# nrf9230_engb_celldsp register map
Vendor: Nordic Semiconductor; Series: nRF92; File version: 1
Registers are 32-bit, read-write, reset 0x0 unless marked. A register's access mark holds for its fields unless they carry their own. Offsets are from the block's base; [hi:lo] are bit positions; 'fields as' and 'values as' point back to an identical list.

## TURBO1 — Decoding 0
Base 0x45009000
Same registers: TURBO0 0x4500B000
0x00 LTETURBODECTASKS wo — Task vector: bit3-SRAMDMASTART bit2-TCMDMASTART bit1-CORESTOP bit0-CORESTART
  [3:0] LTETURBODECTASKS — Task vector - write 1 to position 0 to 3 triggers task
    on write: 1=CoreStart (Start turbo core); 2=CoreStop (Force turbo core stop); 4=TCMDMAStart (Start data read from DSP memory); 8=SRAMDMAStart (Start data write to SRAM)
0x04 TASKS_CORESTART wo — Start Turbo core
  [0] TASKS_CORESTART
    1=Trigger task
0x08 TASKS_CORESTOP wo — Stop Turbo core (forced stop). Decoder stops when on going iteration is ready.
  [0] TASKS_CORESTOP
    1=Trigger task
0x0C TASKS_TCMDMASTART wo — Start data transfer from DSP TCM memory
  [0] TASKS_TCMDMASTART
    1=Trigger task
0x10 TASKS_SRAMDMASTART wo — Start data transfer to MCU SRAM
  [0] TASKS_SRAMDMASTART
    1=Trigger task
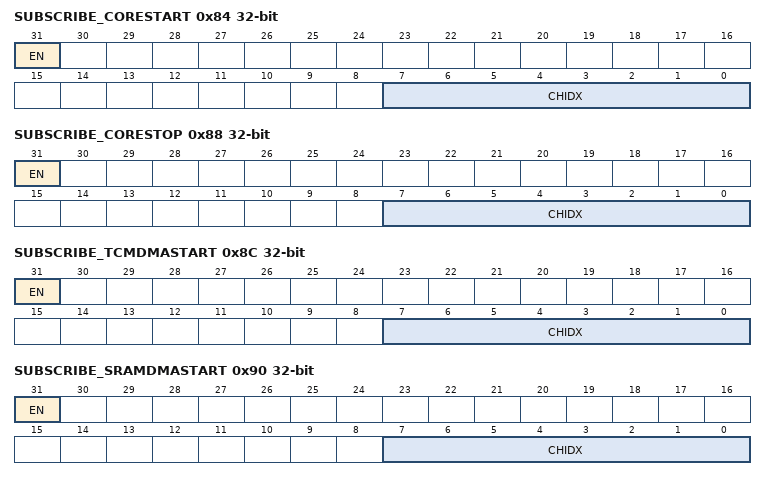
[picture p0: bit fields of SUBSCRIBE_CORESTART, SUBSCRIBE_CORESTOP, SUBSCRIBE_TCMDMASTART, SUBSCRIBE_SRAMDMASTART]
0x84 SUBSCRIBE_CORESTART — Subscribe configuration for task CORESTART
  [31] EN
    0=Disabled (Disable subscription); 1=Enabled (Enable subscription)
  [7:0] CHIDX — DPPI channel that task CORESTART will subscribe to
0x88 SUBSCRIBE_CORESTOP — Subscribe configuration for task CORESTOP
  [31] EN
    values as SUBSCRIBE_CORESTART.EN
  [7:0] CHIDX — DPPI channel that task CORESTOP will subscribe to
0x8C SUBSCRIBE_TCMDMASTART — Subscribe configuration for task TCMDMASTART
  [31] EN
    values as SUBSCRIBE_CORESTART.EN
  [7:0] CHIDX — DPPI channel that task TCMDMASTART will subscribe to
0x90 SUBSCRIBE_SRAMDMASTART — Subscribe configuration for task SRAMDMASTART
  [31] EN
    values as SUBSCRIBE_CORESTART.EN
  [7:0] CHIDX — DPPI channel that task SRAMDMASTART will subscribe to
0x100 LTETURBODECEVENTS ro — Event vector - Reserved (Not used)
  [6:0] LTETURBODECEVENTS — Event vector. Reserved. Always zero
    on read: 0=NotUsed (Read: all zero); 1=Core (Decoder done - bit1 - reg 0x104, write set val = 0x1); 2=DMATCM (TCM DMA transfer done - reg 0x108, write set val = 0x1); 4=DMASRAM (SRAM DMA transfer done - reg 0x10C, write set val = 0x1); 8=NoDMASRAM (CRC failed - No SRAM DMA - reg 0x110, write set val = 0x1); 16=DMATCMFail (TCM DMA bus error detected - reg 0x114, write set val = 0x1); 32=DMASRAMFail (SRAM DMA bus error detected - reg 0x118, write set val = 0x1)
0x104 EVENTS_CORE — Decoder done
  [0] EVENTS_CORE
    0=NotGenerated (Event not generated); 1=Generated (Event generated)
0x108 EVENTS_DMATCM — TCM DMA transfer done
  [0] EVENTS_DMATCM
    values as EVENTS_CORE.EVENTS_CORE
0x10C EVENTS_DMASRAM — SRAM DMA transfer done
  [0] EVENTS_DMASRAM
    values as EVENTS_CORE.EVENTS_CORE
0x110 EVENTS_NODMASRAM — CRC failed - No SRAM DMA
  [0] EVENTS_NODMASRAM
    values as EVENTS_CORE.EVENTS_CORE
0x114 EVENTS_DMATCMFAIL — TCM DMA bus error detected
  [0] EVENTS_DMATCMFAIL
    values as EVENTS_CORE.EVENTS_CORE
0x118 EVENTS_DMASRAMFAIL — SRAM DMA bus error detected
  [0] EVENTS_DMASRAMFAIL
    values as EVENTS_CORE.EVENTS_CORE
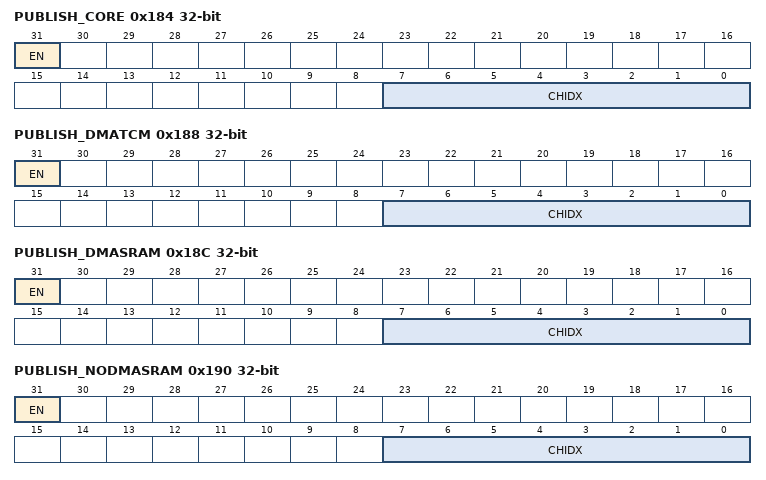
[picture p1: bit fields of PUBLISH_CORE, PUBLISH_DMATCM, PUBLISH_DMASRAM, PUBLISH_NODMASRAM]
0x184 PUBLISH_CORE — Publish configuration for event CORE
  [31] EN
    0=Disabled (Disable publishing); 1=Enabled (Enable publishing)
  [7:0] CHIDX — DPPI channel that event CORE will publish to
0x188 PUBLISH_DMATCM — Publish configuration for event DMATCM
  [31] EN
    values as PUBLISH_CORE.EN
  [7:0] CHIDX — DPPI channel that event DMATCM will publish to
0x18C PUBLISH_DMASRAM — Publish configuration for event DMASRAM
  [31] EN
    values as PUBLISH_CORE.EN
  [7:0] CHIDX — DPPI channel that event DMASRAM will publish to
0x190 PUBLISH_NODMASRAM — Publish configuration for event NODMASRAM
  [31] EN
    values as PUBLISH_CORE.EN
  [7:0] CHIDX — DPPI channel that event NODMASRAM will publish to
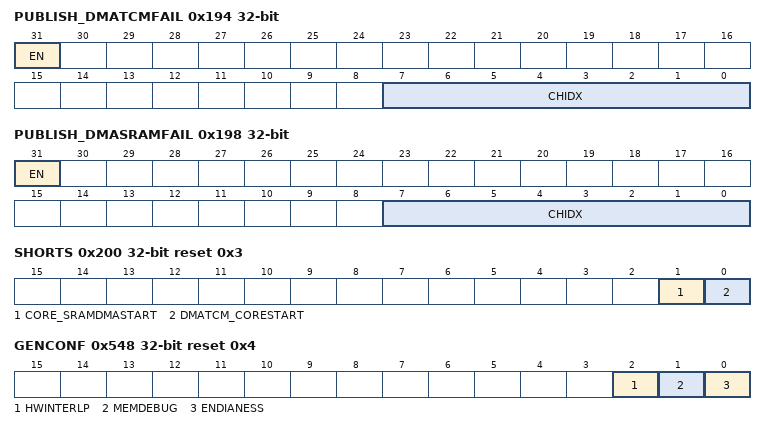
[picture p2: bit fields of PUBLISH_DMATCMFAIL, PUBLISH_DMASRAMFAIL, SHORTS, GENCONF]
0x194 PUBLISH_DMATCMFAIL — Publish configuration for event DMATCMFAIL
  [31] EN
    values as PUBLISH_CORE.EN
  [7:0] CHIDX — DPPI channel that event DMATCMFAIL will publish to
0x198 PUBLISH_DMASRAMFAIL — Publish configuration for event DMASRAMFAIL
  [31] EN
    values as PUBLISH_CORE.EN
  [7:0] CHIDX — DPPI channel that event DMASRAMFAIL will publish to
0x200 SHORTS ro reset 0x3 — Shortcut register
  [1] CORE_SRAMDMASTART — Shortcut between CORE event and SRAMDMASTART task
    on read: 1=Enabled (Shortcut enabled); 0=Disabled (Shortcut disabled)
  [0] DMATCM_CORESTART — Shortcut between DMATCM event and CORESTART task
    values as CORE_SRAMDMASTART
0x204 SET_TCMDONE_CORESTART wo — Enable shortcut
  [0] TCMDONE_CORESTART — Write '1' to Enable TCMDONE to CORESTART shortcut
    on write: 1=Set (Enable)
0x208 CLR_TCMDONE_CORESTART wo — Disable shortcut
  [0] TCMDONE_CORESTART — Write '1' to Disable TCMDONE to CORESTART shortcut
    on write: 1=Clear (Disable)
0x20C SET_COREDONE_SRAMSTART wo — Enable shortcut
  [0] COREDONE_SRAMSTART — Write '1' to Enable COREDONE to SRAMSTART shortcut
    on write: 1=Set (Enable)
0x210 CLR_COREDONE_SRAMSTART wo — Disable shortcut
  [0] COREDONE_SRAMSTART — Write '1' to Disable COREDONE to SRAMSTART shortcut
    on write: 1=Clear (Disable)
0x300 IRQ_COREENABLE — Enable or disable interrupt
  [1] CORE — Enable or disable interrupt for CORE event
    0=Disabled; 1=Enabled
0x304 IRQ_SETCOREENABLE — Enable interrupt
  [1] CORE — Write '1' to Enable interrupt for CORE event
    on read: 0=Disabled (Read: Disabled); 1=Enabled (Read: Enabled) | on write: 1=Set (Enable)
0x308 IRQ_CLRCOREENABLE — Disable interrupt
  [1] CORE — Write '1' to Disable interrupt for CORE event
    on read: 0=Disabled (Read: Disabled); 1=Enabled (Read: Enabled) | on write: 1=Clear (Disable)
0x30C IRQ_TCMDMAENABLE — Enable or disable interrupt
  [2] DMATCM — Enable or disable interrupt for DMATCM event
    0=Disabled; 1=Enabled
0x310 IRQ_SETTCMDMAENABLE — Enable interrupt
  [2] DMATCM — Write '1' to Enable interrupt for DMATCM event
    values as IRQ_SETCOREENABLE.CORE
0x314 IRQ_CLRTCMDMAENABLE — Disable interrupt
  [2] DMATCM — Write '1' to Disable interrupt for DMATCM event
    values as IRQ_CLRCOREENABLE.CORE
0x318 IRQ_SRAMDMAENABLE reset 0x8 — Enable or disable interrupt
  [3] DMASRAM — Enable or disable interrupt for DMASRAM event
    0=Disabled; 1=Enabled
0x31C IRQ_SETSRAMDMAENABLE reset 0x8 — Enable interrupt
  [3] DMASRAM — Write '1' to Enable interrupt for DMASRAM event
    values as IRQ_SETCOREENABLE.CORE
0x320 IRQ_CLRSRAMDMAENABLE reset 0x8 — Disable interrupt
  [3] DMASRAM — Write '1' to Disable interrupt for DMASRAM event
    values as IRQ_CLRCOREENABLE.CORE
0x324 IRQ_NOSRAMDMAENABLE reset 0x10 — Enable or disable interrupt
  [4] NODMASRAM — Enable or disable interrupt for NODMASRAM event
    0=Disabled; 1=Enabled
0x328 IRQ_SETNOSRAMDMAENABLE reset 0x10 — Enable interrupt
  [4] NODMASRAM — Write '1' to Enable interrupt for NODMASRAM event
    values as IRQ_SETCOREENABLE.CORE
0x32C IRQ_CLRNOSRAMDMAENABLE reset 0x10 — Disable interrupt
  [4] NODMASRAM — Write '1' to Disable interrupt for NODMASRAM event
    values as IRQ_CLRCOREENABLE.CORE
0x330 IRQ_TCMDMAFAIL — Enable or disable interrupt
  [5] DMATCMFAIL — Enable or disable interrupt for DMATCMFAIL event
    0=Disabled; 1=Enabled
0x334 IRQ_SETTCMDMAFAIL — Enable interrupt
  [5] DMATCMFAIL — Write '1' to Enable interrupt for DMATCMFAIL event
    values as IRQ_SETCOREENABLE.CORE
0x338 IRQ_CLRTCMDMAFAIL — Disable interrupt
  [5] DMATCMFAIL — Write '1' to Disable interrupt for DMATCMFAIL event
    values as IRQ_CLRCOREENABLE.CORE
0x33C IRQ_SRAMDMAFAIL — Enable or disable interrupt
  [6] DMASRAMFAIL — Enable or disable interrupt for DMASRAMFAIL event
    0=Disabled; 1=Enabled
0x340 IRQ_SETSRAMDMAFAIL — Enable interrupt
  [6] DMASRAMFAIL — Write '1' to Enable interrupt for DMASRAMFAIL event
    values as IRQ_SETCOREENABLE.CORE
0x344 IRQ_CLRSRAMDMAFAIL — Disable interrupt
  [6] DMASRAMFAIL — Write '1' to Disable interrupt for DMASRAMFAIL event
    values as IRQ_CLRCOREENABLE.CORE
0x404 HPCOK2 — Cyclic redundancy checks passed/not passed = 1/0
  [0] HPCOK2
0x408 HPRCRC — Cyclic redundancy check bits, all zeros if CRC passed
  [23:0] HPRCRC
0x40C HPBCOK — The bits of convergence didnt change between the last and previous round =1/0, the zero means they changed
  [0] HPBCOK
0x410 HPSDLST — The last sum of absolute values of soft decisions
  [19:0] HPSDLST
0x414 HPSDPRV — The previous sum of absolute values of soft decisions
  [19:0] HPSDPRV
0x418 HPABS — The sum of absolute values of systematic soft bits
  [16:0] HPABS
0x41C HPTESP — This bit field indicates which early stop predictions are true at the last round. The bits are set as for PHESP by the decoder.
  [3:0] HPTESP
0x420 HPITRD — The number of iterations the turbo decoder executed to decode data
  [4:0] HPITRD
0x500 ENABLE — LTE Turbo Decoder master enable
  [0] ENABLE
    0=Disabled; 1=Enabled
0x504 TDMAA — TCM DMA start address from TCM memory
0x508 TDMASBC — TCM DMA data block size index
  [31:0] TDMASBC — TCM DMA SB data block size index
0x50C SDMAA — SRAM DMA start address to System RAM
0x510 SDMAS — SRAM DMA data block size (words)
0x514 PHN1 reset 0x8C0 — The length of a turbo interleaver. Default value 2240 decimal.
  [12:0] PHN1
0x518 PHMXITR — The maximum number of iterations
  [4:0] PHMXITR
0x51C PHESP — Early stop prediction
  [3:0] PHESP — Early stop prediction: 0000 = maximum rounds 0001 = CRC 0010 = extrinsic signs 0100 = abs sums x000 not in use yet. Any combination of above.
0x520 PHCRC — Turn CRC ON/OFF = 1/0
  [0] PHCRC
0x524 PHABS — Turn the absolute sum calculator ON/OFF = 1/0
  [0] PHABS
0x528 PHCPOLY — A polynomial for cyclic redundancy checks
  [24:0] PHCPOLY — A polynomial for cyclic redundancy checks. Aligned to msb if a degree less than 24. For example, the polynomial D24 + D3 + D + 1 is aligned so that the tap D24 is the 24th bit.
0x52C B00B01 — Interleaver 0th and 1st order terms backward at p(N-2k). Even addresses to read.
  [23:0] B00B01
0x530 B10B11 — Interleaver 0th and 1st order terms backward at p(N-2k + 1). Odd addresses to read.
  [23:0] B10B11
0x534 F800F801 — Interleaver 0th and 1st order terms forward at p(16+2k). Even addresses to read.
  [23:0] F800F801
0x538 F810F811 — Interleaver 0th and 1st order terms forward at p(16+2k+1). Odd addresses to read.
  [23:0] F810F811
0x53C F00F01 — Interleaver 0th and 1st order terms forward at p(2k). Even addresses to write.
  [23:0] F00F01
0x540 F10F11 — Interleaver 0th and 1st order terms forward at p(2k+1). Odd addresses to write.
  [23:0] F10F11
0x544 D2 — A second order interleaver term which is common for all differences
  [11:0] D2
0x548 GENCONF reset 0x4 — A General configuration register
  [2] HWINTERLP — Interleaver parameter calculation by HW
    0=DSPMode (DSP writes the parameters); 1=HWMode (Internal HW calculates the parameters)
  [1] MEMDEBUG — Internal memory debug mode
    0=NormalMode (Functional mode selected); 1=DebugMode (Memory debug mode selected)
  [0] ENDIANESS — SRAM write endianess selection
    0=BigEndian (Byte order big endian); 1=LittleEndian (Byte order little endian)
0x54C DEBUGADDR — Debug address
  [14:0] DebugAddr — Read/write address
0x550 DEBUGDATA
  [31:0] DebugData — Read/write data
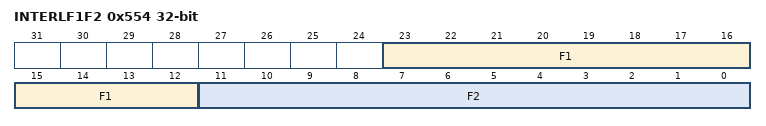
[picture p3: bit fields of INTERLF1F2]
0x554 INTERLF1F2 — f1 and f2 parameters for interleaver parameter calculation
  [23:12] F1 — f1 parameter
  [11:0] F2 — f2 parameter

## Notices in the file
Copyright (c) 2010 - 2024, Nordic Semiconductor ASA
All rights reserved.
Redistribution and use in source and binary forms, with or without modification,
are permitted provided that the following conditions are met:
1. Redistributions of source code must retain the above copyright notice, this
list of conditions and the following disclaimer.
2. Redistributions in binary form, except as embedded into a Nordic
Semiconductor ASA integrated circuit in a product or a software update for
such product, must reproduce the above copyright notice, this list of
conditions and the following disclaimer in the documentation and/or other
materials provided with the distribution.
3. Neither the name of Nordic Semiconductor ASA nor the names of its
contributors may be used to endorse or promote products derived from this
software without specific prior written permission.
4. This software, with or without modification, must only be used with a
Nordic Semiconductor ASA integrated circuit.
5. Any software provided in binary form under this license must not be reverse
engineered, decompiled, modified and/or disassembled.
THIS SOFTWARE IS PROVIDED BY NORDIC SEMICONDUCTOR ASA "AS IS" AND ANY EXPRESS
OR IMPLIED WARRANTIES, INCLUDING, BUT NOT LIMITED TO, THE IMPLIED WARRANTIES
OF MERCHANTABILITY, NONINFRINGEMENT, AND FITNESS FOR A PARTICULAR PURPOSE ARE
DISCLAIMED. IN NO EVENT SHALL NORDIC SEMICONDUCTOR ASA OR CONTRIBUTORS BE
LIABLE FOR ANY DIRECT, INDIRECT, INCIDENTAL, SPECIAL, EXEMPLARY, OR
CONSEQUENTIAL DAMAGES (INCLUDING, BUT NOT LIMITED TO, PROCUREMENT OF SUBSTITUTE
GOODS OR SERVICES; LOSS OF USE, DATA, OR PROFITS; OR BUSINESS INTERRUPTION)
HOWEVER CAUSED AND ON ANY THEORY OF LIABILITY, WHETHER IN CONTRACT, STRICT
LIABILITY, OR TORT (INCLUDING NEGLIGENCE OR OTHERWISE) ARISING IN ANY WAY OUT
OF THE USE OF THIS SOFTWARE, EVEN IF ADVISED OF THE POSSIBILITY OF SUCH DAMAGE.
